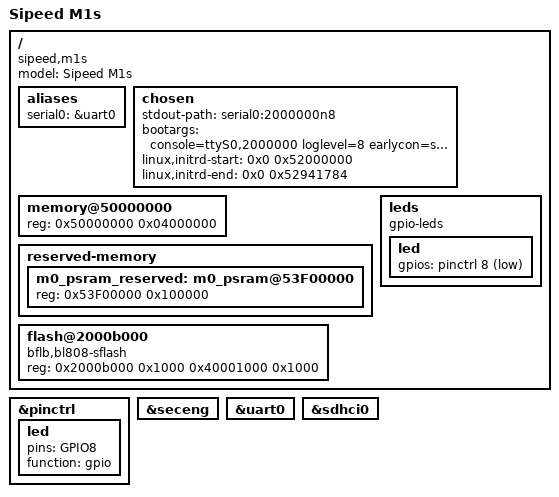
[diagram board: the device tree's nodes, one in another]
// SPDX-License-Identifier: (GPL-2.0+ or MIT)
/*
 * Copyright (C) 2022 Jisheng Zhang <jszhang@kernel.org>
 */

/dts-v1/;

#include "bl808.dtsi"
#include <dt-bindings/gpio/gpio.h>
#include <dt-bindings/leds/common.h>

/ {
	model = "Sipeed M1s";
	compatible = "sipeed,m1s", "bflb,bl808";

	aliases {
		serial0 = &uart0;
	};

	chosen {
		stdout-path = "serial0:2000000n8";
		bootargs = "console=ttyS0,2000000 loglevel=8 earlycon=sbi mtdparts=bflb_sflash:128K(m0-ll),128K(d0-ll),704K(sbi-uboot),64K(uboot-env),4M(kernel),8M(rootfs),3M(rootfs-data) rootfstype=squashfs root=/dev/mtdblock5 init=/sbin/init.sh";
		linux,initrd-start = <0x0 0x52000000>;
		linux,initrd-end = <0x0 0x52941784>;
	};

	memory@50000000 {
		device_type = "memory";
		reg = <0x50000000 0x04000000>;
	};
	reserved-memory {
		#address-cells = <1>;
		#size-cells = <1>;
		ranges;

		m0_psram_reserved: m0_psram@53F00000 {
			reg = <0x53F00000 0x100000>;
			status = "okay";
		};
	};

	flash@2000b000 {
		compatible = "bflb,bl808-sflash";
		reg = <0x2000b000 0x1000 0x40001000 0x1000>;
		#address-cells = <1>;
		#size-cells = <1>;
	};

	leds {
        compatible = "gpio-leds";

        led {
            gpios = <&pinctrl 8 GPIO_ACTIVE_LOW>;
        };
    };
};

&pinctrl {
	status = "okay";

	led {
		pins = "GPIO8";
		function = "gpio";
	};
};

&seceng {
	status = "okay";
};

&uart0 {
	status = "okay";
};

&sdhci0 {
	status = "okay";
};

/*
&ipclic {
	status = "okay";
};
*/
